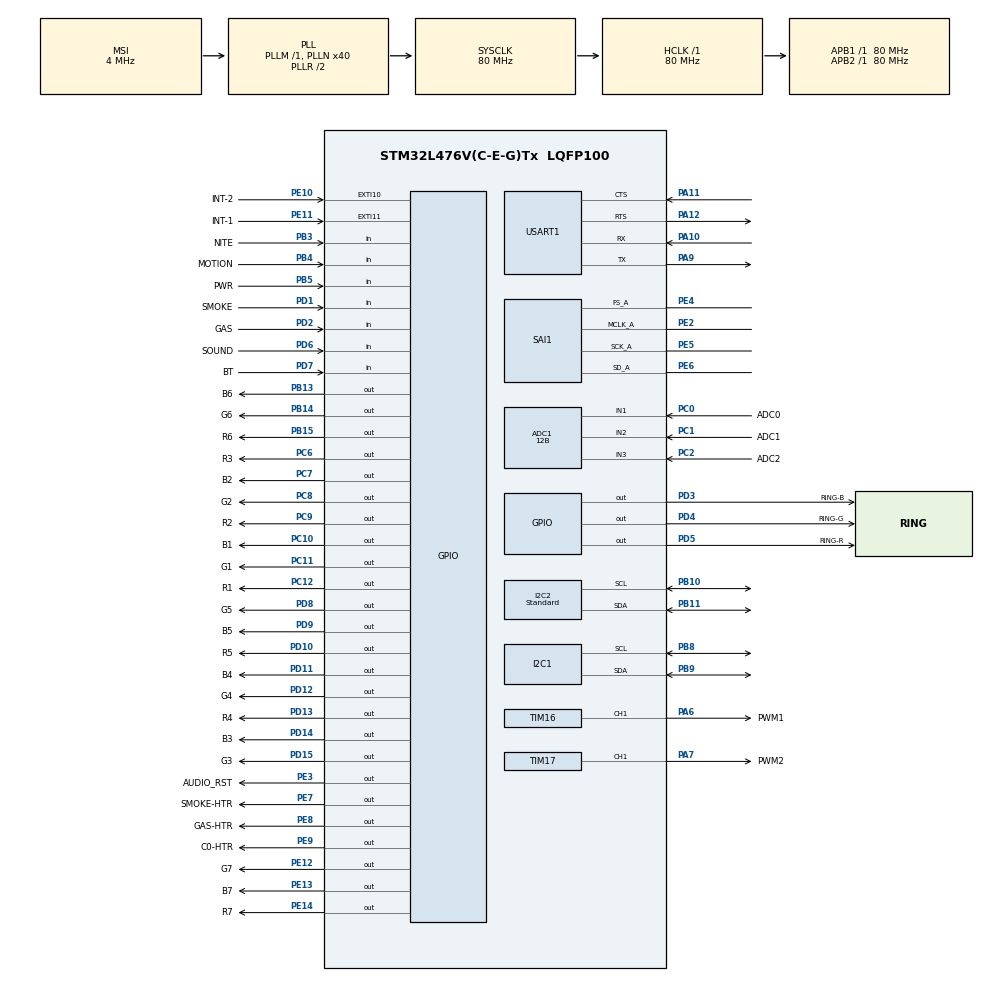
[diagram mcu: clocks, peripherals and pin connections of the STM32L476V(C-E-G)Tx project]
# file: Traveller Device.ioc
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ADC1.Channel-0\#ChannelRegularConversion=ADC_CHANNEL_1
ADC1.Channel-3\#ChannelRegularConversion=ADC_CHANNEL_2
ADC1.Channel-4\#ChannelRegularConversion=ADC_CHANNEL_3
ADC1.ClockPrescaler=ADC_CLOCK_ASYNC_DIV1
ADC1.ContinuousConvMode=ENABLE
ADC1.DMAContinuousRequests=DISABLE
ADC1.DataAlign=ADC_DATAALIGN_RIGHT
ADC1.DiscontinuousConvMode=DISABLE
ADC1.EOCSelection=ADC_EOC_SINGLE_CONV
ADC1.EnableAnalogWatchDog1=false
ADC1.EnableAnalogWatchDog2=false
ADC1.EnableAnalogWatchDog3=false
ADC1.EnableInjectedConversion=DISABLE
ADC1.EnableRegularConversion=ENABLE
ADC1.ExternalTrigConv=ADC_SOFTWARE_START
ADC1.ExternalTrigConvEdge=ADC_EXTERNALTRIGCONVEDGE_NONE
ADC1.LowPowerAutoWait=DISABLE
ADC1.NbrOfConversion=3
ADC1.NbrOfConversionFlag=1
ADC1.OffsetNumber-0\#ChannelRegularConversion=ADC_OFFSET_NONE
ADC1.OffsetNumber-3\#ChannelRegularConversion=ADC_OFFSET_NONE
ADC1.OffsetNumber-4\#ChannelRegularConversion=ADC_OFFSET_NONE
ADC1.Overrun=ADC_OVR_DATA_PRESERVED
ADC1.OversamplingMode=DISABLE
ADC1.Rank-0\#ChannelRegularConversion=1
ADC1.Rank-3\#ChannelRegularConversion=2
ADC1.Rank-4\#ChannelRegularConversion=3
ADC1.Resolution=ADC_RESOLUTION_12B
ADC1.SamplingTime-0\#ChannelRegularConversion=ADC_SAMPLETIME_640CYCLES_5
ADC1.SamplingTime-3\#ChannelRegularConversion=ADC_SAMPLETIME_640CYCLES_5
ADC1.SamplingTime-4\#ChannelRegularConversion=ADC_SAMPLETIME_640CYCLES_5
ADC1.ScanConvMode=ADC_SCAN_ENABLE
ADC1.master=1
Dma.Request0=SAI1_A
Dma.SAI1_A.0.Direction=DMA_MEMORY_TO_PERIPH
Dma.SAI1_A.0.Instance=DMA2_Channel1
Dma.SAI1_A.0.MemDataAlignment=DMA_MDATAALIGN_HALFWORD
Dma.SAI1_A.0.MemInc=DMA_MINC_ENABLE
Dma.SAI1_A.0.Mode=DMA_CIRCULAR
Dma.SAI1_A.0.PeriphDataAlignment=DMA_PDATAALIGN_HALFWORD
Dma.SAI1_A.0.PeriphInc=DMA_PINC_DISABLE
Dma.SAI1_A.0.Priority=DMA_PRIORITY_HIGH
I2C2.Analog_Filter=I2C_ANALOGFILTER_ENABLE
I2C2.I2C_Fall_Time=0
I2C2.I2C_Rise_Time=0
I2C2.I2C_Speed_Mode=I2C_Standard
Mcu.Family=STM32L4
Mcu.Name=STM32L476V(C-E-G)Tx
Mcu.Package=LQFP100
NVIC.DMA2_Channel1_IRQn=true\:0\:0\:false\:false\:true\:false
NVIC.EXTI15_10_IRQn=true\:0\:0\:false\:false\:true\:true
NVIC.I2C1_ER_IRQn=true\:0\:0\:false\:false\:true\:true
NVIC.I2C1_EV_IRQn=true\:0\:0\:false\:false\:true\:true
NVIC.I2C2_ER_IRQn=true\:1\:0\:true\:false\:true\:true
NVIC.I2C2_EV_IRQn=true\:0\:0\:false\:false\:true\:true
NVIC.PriorityGroup=NVIC_PRIORITYGROUP_4
NVIC.SAI1_IRQn=true\:0\:0\:false\:false\:true\:true
PA10.Mode=Asynchronous
PA10.Signal=USART1_RX
PA11.Mode=CTS_RTS
PA11.Signal=USART1_CTS
PA12.Mode=CTS_RTS
PA12.Signal=USART1_RTS
PA6.GPIO_Label=PWM1
PA6.Signal=S_TIM16_CH1
PA7.GPIO_Label=PWM2
PA7.Signal=S_TIM17_CH1
PA9.Mode=Asynchronous
PA9.Signal=USART1_TX
PB10.Mode=I2C
PB10.Signal=I2C2_SCL
PB11.Mode=I2C
PB11.Signal=I2C2_SDA
PB13.GPIO_Label=B6
PB13.Signal=GPIO_Output
PB14.GPIO_Label=G6
PB14.Signal=GPIO_Output
PB15.GPIO_Label=R6
PB15.Signal=GPIO_Output
PB3\ (JTDO-TRACESWO).GPIO_Label=NITE
PB3\ (JTDO-TRACESWO).Signal=GPIO_Input
PB4\ (NJTRST).GPIO_Label=MOTION
PB4\ (NJTRST).Signal=GPIO_Input
PB5.GPIO_Label=PWR
PB5.Signal=GPIO_Input
PB8.Mode=I2C
PB8.Signal=I2C1_SCL
PB9.Mode=I2C
PB9.Signal=I2C1_SDA
PC0.GPIO_Label=ADC0
PC0.Signal=ADCx_IN1
PC1.GPIO_Label=ADC1
PC1.Signal=ADCx_IN2
PC10.GPIO_Label=B1
PC10.Signal=GPIO_Output
PC11.GPIO_Label=G1
PC11.Signal=GPIO_Output
PC12.GPIO_Label=R1
PC12.Signal=GPIO_Output
PC2.GPIO_Label=ADC2
PC2.Signal=ADCx_IN3
PC6.GPIO_Label=R3
PC6.Signal=GPIO_Output
PC7.GPIO_Label=B2
PC7.Signal=GPIO_Output
PC8.GPIO_Label=G2
PC8.Signal=GPIO_Output
PC9.GPIO_Label=R2
PC9.Signal=GPIO_Output
PD1.GPIO_Label=SMOKE
PD1.Signal=GPIO_Input
PD10.GPIO_Label=R5
PD10.Signal=GPIO_Output
PD11.GPIO_Label=B4
PD11.Signal=GPIO_Output
PD12.GPIO_Label=G4
PD12.Signal=GPIO_Output
PD13.GPIO_Label=R4
PD13.Signal=GPIO_Output
PD14.GPIO_Label=B3
PD14.Signal=GPIO_Output
PD15.GPIO_Label=G3
PD15.Signal=GPIO_Output
PD2.GPIO_Label=GAS
PD2.Signal=GPIO_Input
PD3.GPIO_Label=RING-B
PD3.Signal=GPIO_Output
PD4.GPIO_Label=RING-G
PD4.Signal=GPIO_Output
PD5.GPIO_Label=RING-R
PD5.Signal=GPIO_Output
PD6.GPIO_Label=SOUND
PD6.Signal=GPIO_Input
PD7.GPIO_Label=BT
PD7.Signal=GPIO_Input
PD8.GPIO_Label=G5
PD8.Signal=GPIO_Output
PD9.GPIO_Label=B5
PD9.Signal=GPIO_Output
PE10.GPIO_Label=INT-2
PE10.Signal=GPXTI10
PE11.GPIO_Label=INT-1
PE11.Signal=GPXTI11
PE12.GPIO_Label=G7
PE12.Signal=GPIO_Output
PE13.GPIO_Label=B7
PE13.Signal=GPIO_Output
PE14.GPIO_Label=R7
PE14.Signal=GPIO_Output
PE2.Mode=SAI_A_MasterWithClock
PE2.Signal=SAI1_MCLK_A
PE3.GPIO_Label=AUDIO_RST
PE3.Signal=GPIO_Output
PE4.Mode=SAI_A_MasterWithClock
PE4.Signal=SAI1_FS_A
PE5.Mode=SAI_A_MasterWithClock
PE5.Signal=SAI1_SCK_A
PE6.Mode=SAI_A_MasterWithClock
PE6.Signal=SAI1_SD_A
PE7.GPIO_Label=SMOKE-HTR
PE7.Signal=GPIO_Output
PE8.GPIO_Label=GAS-HTR
PE8.Signal=GPIO_Output
PE9.GPIO_Label=C0-HTR
PE9.Signal=GPIO_Output
ProjectManager.HeapSize=0x200
ProjectManager.StackSize=0x400
ProjectManager.TargetToolchain=MDK-ARM V5
RCC.ADCFreq_Value=24000000
RCC.AHBFreq_Value=80000000
RCC.APB1Freq_Value=80000000
RCC.APB1TimFreq_Value=80000000
RCC.APB2Freq_Value=80000000
RCC.APB2TimFreq_Value=80000000
RCC.CortexFreq_Value=80000000
RCC.HCLKFreq_Value=80000000
RCC.HSE_VALUE=8000000
RCC.HSI_VALUE=16000000
RCC.LSE_VALUE=32768
RCC.MSI_VALUE=4000000
RCC.PLLN=40
RCC.PLLSAI1N=48
RCC.PLLSAI1P=RCC_PLLP_DIV17
RCC.PLLSAI1R=RCC_PLLR_DIV8
RCC.SYSCLKFreq_VALUE=80000000
RCC.SYSCLKSource=RCC_SYSCLKSOURCE_PLLCLK
RCC.USBFreq_Value=96000000
RCC.VCOOutputFreq_Value=160000000
SAI1.ActiveFrameLength-SAI_A_MasterWithClock=16
SAI1.AudioFrequency-SAI_A_MasterWithClock=SAI_AUDIO_FREQUENCY_22K
SAI1.DataSize-SAI_A_MasterWithClock=SAI_DATASIZE_16
SAI1.ErrorAudioFreq-SAI_A_MasterWithClock=-88.51 %
SAI1.FIFOThreshold-SAI_A_MasterWithClock=SAI_FIFOTHRESHOLD_1QF
SAI1.FSDefinition-SAI_A_MasterWithClock=SAI_FS_CHANNEL_IDENTIFICATION
SAI1.FSOffset-SAI_A_MasterWithClock=SAI_FS_BEFOREFIRSTBIT
SAI1.FrameLength-SAI_A_MasterWithClock=32
SAI1.Instance-SAI_A_MasterWithClock=SAI$Index_Block_A
SAI1.MClockEnable-SAI_A_MasterWithClock=SAI_MASTERCLOCK_ENABLE
SAI1.OutputDrive-SAI_A_MasterWithClock=SAI_OUTPUTDRIVE_ENABLE
SAI1.RealAudioFreq-SAI_A_MasterWithClock=22.058 KHz
SAI1.SlotActive-SAI_A_MasterWithClock=0x00000003
SAI1.SlotNumber-SAI_A_MasterWithClock=2
SAI1.Synchro-SAI_A_MasterWithClock=SAI_ASYNCHRONOUS
SAI1.VirtualMode-SAI_A_MasterWithClock=VM_MASTER
SAI1.VirtualSlotActive-SAI_A_MasterWithClock=SAI_SLOT_USERSETTING
SAI1.VirtualSlotActive0-SAI_A_MasterWithClock=true
SAI1.VirtualSlotActive1-SAI_A_MasterWithClock=true
SH.ADCx_IN1.0=ADC1_IN1,IN1-Single-Ended
SH.ADCx_IN2.0=ADC1_IN2,IN2-Single-Ended
SH.ADCx_IN3.0=ADC1_IN3,IN3-Single-Ended
SH.S_TIM16_CH1.0=TIM16_CH1,PWM Generation1 CH1
SH.S_TIM17_CH1.0=TIM17_CH1,PWM Generation1 CH1
TIM16.AutoReloadPreload=TIM_AUTORELOAD_PRELOAD_DISABLE
TIM16.Channel=TIM_CHANNEL_1
TIM16.Period=40-1
TIM16.Prescaler=10000-1
TIM16.Pulse=0
TIM17.Channel=TIM_CHANNEL_1
TIM17.Period=40-1
TIM17.Prescaler=10000-1
TIM17.Pulse=9
TIM6.Period=40
TIM6.Prescaler=20000-1
TIM6.TIM_MasterOutputTrigger=TIM_TRGO_UPDATE
USART1.VirtualMode-Asynchronous=VM_ASYNC
VP_TIM16_VS_ClockSourceINT.Mode=Enable_Timer
VP_TIM17_VS_ClockSourceINT.Mode=Enable_Timer
VP_TIM6_VS_ClockSourceINT.Mode=Enable_Timer
VREF+.Mode=InternalMode
VREF+.Signal=VREFBUF_OUT
board=custom

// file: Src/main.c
/**
  ******************************************************************************
  * @file           : main.c
  * @brief          : Main program body
  ******************************************************************************
  ** This notice applies to any and all portions of this file
  * that are not between comment pairs USER CODE BEGIN and
  * USER CODE END. Other portions of this file, whether
  * inserted by the user or by software development tools
  * are owned by their respective copyright owners.
  *
  * COPYRIGHT(c) 2018 STMicroelectronics
  *
  * Redistribution and use in source and binary forms, with or without modification,
  * are permitted provided that the following conditions are met:
  *   1. Redistributions of source code must retain the above copyright notice,
  *      this list of conditions and the following disclaimer.
  *   2. Redistributions in binary form must reproduce the above copyright notice,
  *      this list of conditions and the following disclaimer in the documentation
  *      and/or other materials provided with the distribution.
  *   3. Neither the name of STMicroelectronics nor the names of its contributors
  *      may be used to endorse or promote products derived from this software
  *      without specific prior written permission.
  *
  * THIS SOFTWARE IS PROVIDED BY THE COPYRIGHT HOLDERS AND CONTRIBUTORS "AS IS"
  * AND ANY EXPRESS OR IMPLIED WARRANTIES, INCLUDING, BUT NOT LIMITED TO, THE
  * IMPLIED WARRANTIES OF MERCHANTABILITY AND FITNESS FOR A PARTICULAR PURPOSE ARE
  * DISCLAIMED. IN NO EVENT SHALL THE COPYRIGHT HOLDER OR CONTRIBUTORS BE LIABLE
  * FOR ANY DIRECT, INDIRECT, INCIDENTAL, SPECIAL, EXEMPLARY, OR CONSEQUENTIAL
  * DAMAGES (INCLUDING, BUT NOT LIMITED TO, PROCUREMENT OF SUBSTITUTE GOODS OR
  * SERVICES; LOSS OF USE, DATA, OR PROFITS; OR BUSINESS INTERRUPTION) HOWEVER
  * CAUSED AND ON ANY THEORY OF LIABILITY, WHETHER IN CONTRACT, STRICT LIABILITY,
  * OR TORT (INCLUDING NEGLIGENCE OR OTHERWISE) ARISING IN ANY WAY OUT OF THE USE
  * OF THIS SOFTWARE, EVEN IF ADVISED OF THE POSSIBILITY OF SUCH DAMAGE.
  *
  ******************************************************************************
  */
#include "main.h"
#include "stm32l4xx_hal.h"

/* USER CODE BEGIN Includes */
#define ACC_DEV 0x50
#define LIS3DE_CTRL_REG1             0x20U
#define LIS3DE_CLICK_THS             0x3AU
#define LIS3DE_TIME_LIMIT            0x3BU
#define LIS3DE_CTRL_REG6             0x25U
#define LIS3DE_CLICK_CFG             0x38U
#define AUDIO_FILE_ADDRESS   				0x08098CF0//0x08080000 // 0x08098CF0

// MOTION : 0x08080000 SMOKE : 0x08098CF0 GAS : 0x080B19E0
#define TEMP_ADD (0x40<<1)
__IO int16_t                 UpdatePointer = -1;

#define AUDIO_FILE_SIZE      (100*1024)
#define PLAY_HEADER          	0x2c//0x2C
#define PLAY_BUFF_SIZE       4096
DMA_HandleTypeDef            hSaiDma;

uint16_t                      PlayBuff[PLAY_BUFF_SIZE];
void readSensors();
void trigger();
void temp_hum();
/* USER CODE END Includes */

ADC_HandleTypeDef hadc1;

I2C_HandleTypeDef hi2c1;
I2C_HandleTypeDef hi2c2;

SAI_HandleTypeDef hsai_BlockA1;
DMA_HandleTypeDef hdma_sai1_a;

TIM_HandleTypeDef htim6;
TIM_HandleTypeDef htim16;
TIM_HandleTypeDef htim17;

UART_HandleTypeDef huart1;

/* USER CODE BEGIN PV */
SAI_HandleTypeDef    SaiHandle;
AUDIO_DrvTypeDef            *audio_drv;
#define REFdebounce 50

/* Private variables ---------------------------------------------------------*/
uint32_t flame_a0 = 0x00;
uint32_t CO_a1 = 0x00;
uint32_t smoke_a2 = 0x00;
uint32_t heaterTime = 0x00;
uint32_t offHeaterTime = 0x00;
uint32_t flashredTime = 0x00;
float flameV;
float coV;
float smokeV;
_Bool offCountHeater = 0x00;
_Bool countHeater = 0x00;
_Bool POWERON = 0x00;
_Bool	SMOKEON =	0x00;
_Bool	GASON		=	0x00;
_Bool	MOVEON	=	0x00;
_Bool	SOUNDON	=	0x00;
_Bool NITEON	= 0x00;
_Bool	 SCANROOM = 0x00;
_Bool	BTON		=	0x00;
_Bool POWERON_State = 0x00;
_Bool PWSW = 0x00;
_Bool clear_1 = 1;
_Bool clear_2 = 1;
_Bool clear_3 = 1;
_Bool clear_4 = 1;
_Bool clear_5 = 1;
_Bool clear_6 = 1;
_Bool redCO = 0x00;
_Bool redSmoke = 0x00;
_Bool redFlame = 0x00;
_Bool flashRED = 0x00;
_Bool motionFlag = 0x00;
_Bool firsttimeonly = 0x01;
uint8_t cntboot = 0x00;
uint8_t readAcceloro = 0x00;
uint32_t POWERON_1 = 0;
uint32_t POWERON_0 = 0;
uint32_t sensors 	=	0;
uint32_t sensorsM 	=	0;

uint32_t	SMOKEON_1 =	0x00;
uint32_t	SMOKEON_0 =	0x00;

uint32_t	GASON_1		=	0x00;
uint32_t	GASON_0		=	0x00;

uint32_t	MOVEON_1	=	0x00;
uint32_t	MOVEON_0	=	0x00;

uint32_t	SOUNDON_1	=	0x00;
uint32_t	SOUNDON_0	=	0x00;

uint32_t NITEON_1	= 0x00;
uint32_t NITEON_0	= 0x00;

uint32_t	 SCANROOM_1 = 0x00;
uint32_t	 SCANROOM_0 = 0x00;

uint32_t	BTON_1		=	0x00;
uint32_t	BTON_0		=	0x00;
uint8_t reg1;
uint8_t temph[2] = {0U, 0U};

uint16_t R_HUM = 0x00;
uint16_t R_TEMP = 0x00;

float A_HUM;
float A_TEMP;
/* USER CODE END PV */

void SystemClock_Config(void);
static void MX_GPIO_Init(void);
static void MX_DMA_Init(void);
static void MX_ADC1_Init(void);
static void MX_I2C1_Init(void);
static void MX_I2C2_Init(void);
static void MX_SAI1_Init(void);
static void MX_TIM16_Init(void);
static void MX_TIM17_Init(void);
static void MX_USART1_UART_Init(void);
static void MX_TIM6_Init(void);

void HAL_TIM_MspPostInit(TIM_HandleTypeDef *htim);

/* USER CODE BEGIN PFP */
void heartBeat_loop(uint8_t initial_val, uint8_t end_val, uint8_t n);
void heartBeat_loop2(uint8_t initial_val, uint8_t end_val, uint8_t n);
void test_pwm_blink(void);
void startupF(void);
void shutF(void);
/* Private function prototypes -----------------------------------------------*/

/* USER CODE END PFP */

/* USER CODE BEGIN 0 */
static void Playback_Init(void)
{

	 __HAL_SAI_ENABLE(&hsai_BlockA1);

	if(CS43L22_ID!= cs43l22_drv.ReadID(AUDIO_I2C_ADDRESS))
  {
    Error_Handler();
  }

  audio_drv = &cs43l22_drv;
  audio_drv->Reset(AUDIO_I2C_ADDRESS);
  if(0 != audio_drv->Init(AUDIO_I2C_ADDRESS, OUTPUT_DEVICE_SPEAKER, 100, AUDIO_FREQUENCY_22K))
  {
    Error_Handler();
  }
}
/* USER CODE END 0 */

int main(void)
{

  /* MCU Configuration----------------------------------------------------------*/

  /* Reset of all peripherals, Initializes the Flash interface and the Systick. */
  HAL_Init();

  /* Configure the system clock */
  SystemClock_Config();

  /* USER CODE BEGIN SysInit */
  uint32_t PlaybackPosition   = PLAY_BUFF_SIZE + PLAY_HEADER;
  /* USER CODE END SysInit */

  /* Initialize all configured peripherals */
  MX_GPIO_Init();
  MX_DMA_Init();
  MX_ADC1_Init();
  MX_I2C1_Init();
  MX_I2C2_Init();
  MX_SAI1_Init();
  MX_TIM16_Init();
  MX_TIM17_Init();
  MX_USART1_UART_Init();
  MX_TIM6_Init();
  /* USER CODE BEGIN 2 */
//	HAL_I2C_Master_Transmit(&hi2c1, 0xFF, i2c_Data, 4, 5000);
//	HAL_I2C_Mem_Read(&hi2c1,0x28U, 0x0FU,I2C_MEMADD_SIZE_8BIT, &readAcceloro, 1, 1000);
	HAL_TIM_PWM_Start(&htim16, TIM_CHANNEL_1); //ring light intestiy
	HAL_TIM_PWM_Start(&htim17, TIM_CHANNEL_1);
	//if(*((uint64_t *)AUDIO_FILE_ADDRESS) != 0x017EFE2446464952 ) Error_Handler();
	Playback_Init(); // volume and frequency of audio intitilistation

//	for(int i=0; i < PLAY_BUFF_SIZE; i+=2)
//  {
//    PlayBuff[i]=*((__IO uint16_t *)(AUDIO_FILE_ADDRESS + PLAY_HEADER + i));
//  }
//
//  /* Start the playback */
//  if(0 != audio_drv->Play(AUDIO_I2C_ADDRESS, NULL, 0))
//  {
//    Error_Handler();
//  }
 // if(HAL_OK != HAL_SAI_Transmit_DMA(&hsai_BlockA1, (uint8_t *)PlayBuff, PLAY_BUFF_SIZE)) // should not start here as no audio in the buffer yet
  //{
  //  Error_Handler();
  //}

	countHeater = 0x01;
	//SETTING FOR I2C FOR INTERUPT THE MOTION
	reg1 = 0x77;
	HAL_I2C_Mem_Write(&hi2c1,ACC_DEV, LIS3DE_CTRL_REG1,I2C_MEMADD_SIZE_8BIT, (uint8_t*)&reg1, 1, 1000); // set speed 400khz
	reg1 = 0x69U;//0x12U;
	HAL_Delay(10);
	HAL_I2C_Mem_Write(&hi2c1,ACC_DEV, LIS3DE_CLICK_THS,I2C_MEMADD_SIZE_8BIT, (uint8_t*)&reg1, 1, 1000); //Click threshold set
	reg1 = 0x33U;
	HAL_Delay(10);
	HAL_I2C_Mem_Write(&hi2c1,ACC_DEV, LIS3DE_TIME_LIMIT,I2C_MEMADD_SIZE_8BIT, (uint8_t*)&reg1, 1, 1000);
	HAL_Delay(10);
	reg1 = 0x80U;
	HAL_I2C_Mem_Write(&hi2c1,ACC_DEV, LIS3DE_CTRL_REG6,I2C_MEMADD_SIZE_8BIT, (uint8_t*)&reg1, 1, 1000);
	HAL_Delay(10);
	reg1 = 0x5U;
	HAL_I2C_Mem_Write(&hi2c1,ACC_DEV, LIS3DE_CLICK_CFG,I2C_MEMADD_SIZE_8BIT, (uint8_t*)&reg1, 1, 1000);
	HAL_Delay(10);

	//END OF SETTING FOR I2C FOR INTERUPT THE MOTION

	//START OF READ TEMP
	reg1 = 0xE5; // hold master signal
	HAL_I2C_Mem_Read(&hi2c1, TEMP_ADD, reg1,I2C_MEMADD_SIZE_8BIT, temph, 2, 1000);
	R_HUM = (uint16_t) ((temph[0]<<8) | temph[1]);
	A_HUM = (float)(((125.0 * R_HUM) / 65536.0) - 6.0);
	if(A_HUM < 0)
    A_HUM =  0;
  else if(A_HUM > 100)
    A_HUM = 100;
	reg1 = 0xE0;

	HAL_I2C_Mem_Read(&hi2c1, TEMP_ADD, reg1,I2C_MEMADD_SIZE_8BIT, temph, 2, 1000);
	R_TEMP = (uint16_t) ((temph[0]<<8) | temph[1]);
	A_TEMP = (float)(((175.72 * R_TEMP) / 65536.0) - 46.85);

	//END OF READ TEMP
	motionFlag = 0x0U;
  /* USER CODE END 2 */

  /* Infinite loop */
  /* USER CODE BEGIN WHILE */
  while (1)
  {

		//int position = UpdatePointer;
    //UpdatePointer = -1;
    // Playback when trigger motion
		if(motionFlag & ((sensors >> 7) & 1))
		{
			// copy first part for only one time
			if(firsttimeonly)
		{
			for(int i=0; i < PLAY_BUFF_SIZE; i+=2)
			{
				PlayBuff[i]=*((__IO uint16_t *)(0x08080000 + PLAY_HEADER + i));
			}
				firsttimeonly = 0x00;
				HAL_SAI_Transmit_DMA(&hsai_BlockA1, (uint8_t *)PlayBuff, PLAY_BUFF_SIZE); // try this as each time need to say which chunk of memory buffer to read the data frm
				HAL_SAI_DMAResume(&hsai_BlockA1); // this is because there in trigger() is pause the playback basically means mute the amp z
		}

		int position = UpdatePointer;
    UpdatePointer = -1;

		for(int i = 0; i < PLAY_BUFF_SIZE/2; i++)
    {
      PlayBuff[i+position] = *(uint16_t *)(0x08080000 + PlaybackPosition);
      PlaybackPosition+=2;
    }

		if((PlaybackPosition+PLAY_BUFF_SIZE/2) > AUDIO_FILE_SIZE)
    {
      PlaybackPosition = PLAY_HEADER;
    }

		}

		// smoke code start

				if(redSmoke & ((sensors >> 4) & 1))
		{
			// copy first part for only one time
			if(firsttimeonly)
		{
			for(int i=0; i < PLAY_BUFF_SIZE; i+=2)
			{
				PlayBuff[i]=*((__IO uint16_t *)(0x08098CF0 + PLAY_HEADER + i));
			}
				firsttimeonly = 0x00;
				HAL_SAI_Transmit_DMA(&hsai_BlockA1, (uint8_t *)PlayBuff, PLAY_BUFF_SIZE); // try this as each time need to say which chunk of memory buffer to read the data frm
				HAL_SAI_DMAResume(&hsai_BlockA1); // this is because there in trigger() is pause the playback basically means mute the amp z
		}

		int position = UpdatePointer;
    UpdatePointer = -1;

		for(int i = 0; i < PLAY_BUFF_SIZE/2; i++)
    {
      PlayBuff[i+position] = *(uint16_t *)(0x08098CF0 + PlaybackPosition);
      PlaybackPosition+=2;
    }

		if((PlaybackPosition+PLAY_BUFF_SIZE/2) > AUDIO_FILE_SIZE)
    {
      PlaybackPosition = PLAY_HEADER;
    }

		}
		//smoke code end

		//gas code start
		if(redCO & ((sensors >> 5) & 1))
		{
			// copy first part for only one time
			if(firsttimeonly)
		{
			for(int i=0; i < PLAY_BUFF_SIZE; i+=2)
			{
				PlayBuff[i]=*((__IO uint16_t *)(0x080B19E0 + PLAY_HEADER + i));
			}
				firsttimeonly = 0x00;
				HAL_SAI_Transmit_DMA(&hsai_BlockA1, (uint8_t *)PlayBuff, PLAY_BUFF_SIZE); // try this as each time need to say which chunk of memory buffer to read the data frm
				HAL_SAI_DMAResume(&hsai_BlockA1); // this is because there in trigger() is pause the playback basically means mute the amp z
		}

		int position = UpdatePointer;
    UpdatePointer = -1;

		for(int i = 0; i < PLAY_BUFF_SIZE/2; i++)
    {
      PlayBuff[i+position] = *(uint16_t *)(0x080B19E0 + PlaybackPosition);
      PlaybackPosition+=2;
    }

		if((PlaybackPosition+PLAY_BUFF_SIZE/2) > AUDIO_FILE_SIZE)
    {
      PlaybackPosition = PLAY_HEADER;
    }

		}
		// gas code end

		//while(UpdatePointer==-1){

		//}

    /* Upate the first or the second part of the buffer */
//    for(int i = 0; i < PLAY_BUFF_SIZE/2; i++)
//    {
//      PlayBuff[i+position] = *(uint16_t *)(AUDIO_FILE_ADDRESS + PlaybackPosition);
//      PlaybackPosition+=2;
//    }

//    /* check the end of the file */
//    if((PlaybackPosition+PLAY_BUFF_SIZE/2) > AUDIO_FILE_SIZE)
//    {
//      PlaybackPosition = PLAY_HEADER;
//    }
//
//    if(UpdatePointer != -1)
//    {
//      /* Buffer update time is too long compare to the data transfer time */
//      Error_Handler();
//    }
//
		//Playback_Init();
		if(PWSW) // PWR ON [TurnON001]
		{
			//HAL_GPIO_WritePin(B7_GPIO_Port,B7_Pin,GPIO_PIN_SET);
			//HAL_Delay(500);
			//test_pwm_blink();
			//START
			if(cntboot < 1) //Run this for only first time booting
			{
				HAL_SAI_DMAPause(&hsai_BlockA1);
				HAL_GPIO_WritePin(RING_B_GPIO_Port, RING_B_Pin, GPIO_PIN_SET);
				HAL_GPIO_WritePin(B7_GPIO_Port,B7_Pin,GPIO_PIN_SET);
				cntboot=+1;
				heartBeat_loop2(0,39,1);
				heartBeat_loop(39,9,0);
				heartBeat_loop(9,39,1);
				heartBeat_loop(39,3,0);
				heartBeat_loop(3,39,1);
				heartBeat_loop(39,3,0);
				heartBeat_loop(3,39,1);
				heartBeat_loop(39,3,0);
				heartBeat_loop(3,9,1);
				HAL_SAI_DMAResume(&hsai_BlockA1);
			}

			//Read sensors
			readSensors();
			trigger();
			if((SCANROOM) & (PWSW))
			{
				HAL_SAI_DMAPause(&hsai_BlockA1);
				HAL_GPIO_WritePin(RING_B_GPIO_Port, RING_B_Pin, GPIO_PIN_SET);
				heartBeat_loop2(0,39,1);
				heartBeat_loop(39,9,0);
				heartBeat_loop(9,39,1);
				heartBeat_loop(39,3,0);
				heartBeat_loop(3,39,1);
				heartBeat_loop(39,3,0);
				heartBeat_loop(3,39,1);
				heartBeat_loop(39,3,0);
				heartBeat_loop(3,9,1);
				SCANROOM = 0;
				HAL_SAI_DMAResume(&hsai_BlockA1);
			}

			if((sensors >> 4) & 1)
			{
				if(redSmoke)
				{
				HAL_GPIO_WritePin(B1_GPIO_Port, B1_Pin, GPIO_PIN_RESET);
				HAL_GPIO_WritePin(R1_GPIO_Port, R1_Pin, GPIO_PIN_SET);
				}
				else
				{
				HAL_GPIO_WritePin(R1_GPIO_Port, R1_Pin, GPIO_PIN_RESET);
				HAL_GPIO_WritePin(B1_GPIO_Port, B1_Pin, GPIO_PIN_SET);
				}
			}
			else
			{
				HAL_GPIO_WritePin(B1_GPIO_Port, B1_Pin, GPIO_PIN_RESET);
				HAL_GPIO_WritePin(R1_GPIO_Port, R1_Pin, GPIO_PIN_RESET);
			}

			if((sensors >> 5) & 1)
			{
				if(redCO)
				{
					HAL_GPIO_WritePin(B2_GPIO_Port, B2_Pin, GPIO_PIN_RESET);
					HAL_GPIO_WritePin(R2_GPIO_Port, R2_Pin, GPIO_PIN_SET);
				}
				else
				{
				HAL_GPIO_WritePin(B2_GPIO_Port, B2_Pin, GPIO_PIN_SET);
				HAL_GPIO_WritePin(R2_GPIO_Port, R2_Pin, GPIO_PIN_RESET);
				}
			}
			else
			{
				HAL_GPIO_WritePin(B2_GPIO_Port, B2_Pin, GPIO_PIN_RESET);
				HAL_GPIO_WritePin(R2_GPIO_Port, R2_Pin, GPIO_PIN_RESET);
			}
			if((sensors >> 6) & 1)
			{
				HAL_GPIO_WritePin(B5_GPIO_Port, B5_Pin, GPIO_PIN_SET);

			}
			else
			{
				HAL_GPIO_WritePin(B5_GPIO_Port, B5_Pin, GPIO_PIN_RESET);
			}

			if((sensors >> 7) & 1) // MOTION LIGHT
			{
				if(motionFlag)
				{
					HAL_GPIO_WritePin(B6_GPIO_Port, B6_Pin, GPIO_PIN_RESET);
					HAL_GPIO_WritePin(R6_GPIO_Port, R6_Pin, GPIO_PIN_SET);
				}
				else
				{
				HAL_GPIO_WritePin(B6_GPIO_Port, B6_Pin, GPIO_PIN_SET);
				HAL_GPIO_WritePin(R6_GPIO_Port, R6_Pin, GPIO_PIN_RESET);
				}
				//HAL_GPIO_WritePin(B6_GPIO_Port, B6_Pin, GPIO_PIN_SET);
			}
			else
			{
				HAL_GPIO_WritePin(B6_GPIO_Port, B6_Pin, GPIO_PIN_RESET);
				HAL_GPIO_WritePin(R6_GPIO_Port, R6_Pin, GPIO_PIN_RESET);
			}

			if((sensors >> 8) & 1)
			{
				HAL_GPIO_WritePin(B3_GPIO_Port, B3_Pin, GPIO_PIN_SET);
			}
			else
			{
				HAL_GPIO_WritePin(B3_GPIO_Port, B3_Pin, GPIO_PIN_RESET);
			}

			if((sensors >> 9) & 1)
			{
				HAL_GPIO_WritePin(B4_GPIO_Port, B4_Pin, GPIO_PIN_SET);
			}
			else
			{
				HAL_GPIO_WritePin(B4_GPIO_Port, B4_Pin, GPIO_PIN_RESET);
			}

		}
		else //PWR OFF  [TurnOFF001]
		{
			if(cntboot>=1) // run this if the turn on routine have run before.
				{
					//Off light S
					heartBeat_loop2(9,3,0);
					heartBeat_loop(3,39,1);
					heartBeat_loop(39,3,0);
					heartBeat_loop(3,39,1);
					heartBeat_loop(39,3,0);
					heartBeat_loop(3,39,1);
					heartBeat_loop(39,9,0);
					heartBeat_loop(9,39,1);
					heartBeat_loop(39,1,0);
				}

			HAL_GPIO_WritePin(RING_B_GPIO_Port, RING_B_Pin, GPIO_PIN_RESET);
			HAL_GPIO_WritePin(B7_GPIO_Port,B7_Pin,GPIO_PIN_RESET);

			cntboot=0;
		}

  /* USER CODE END WHILE */

  }

}

void SystemClock_Config(void)
{

  RCC_OscInitTypeDef RCC_OscInitStruct;
  RCC_ClkInitTypeDef RCC_ClkInitStruct;
  RCC_PeriphCLKInitTypeDef PeriphClkInit;

    /**Initializes the CPU, AHB and APB busses clocks
    */
  RCC_OscInitStruct.OscillatorType = RCC_OSCILLATORTYPE_MSI;
  RCC_OscInitStruct.MSIState = RCC_MSI_ON;
  RCC_OscInitStruct.MSICalibrationValue = 0;
  RCC_OscInitStruct.MSIClockRange = RCC_MSIRANGE_6;
  RCC_OscInitStruct.PLL.PLLState = RCC_PLL_ON;
  RCC_OscInitStruct.PLL.PLLSource = RCC_PLLSOURCE_MSI;
  RCC_OscInitStruct.PLL.PLLM = 1;
  RCC_OscInitStruct.PLL.PLLN = 40;
  RCC_OscInitStruct.PLL.PLLP = RCC_PLLP_DIV7;
  RCC_OscInitStruct.PLL.PLLQ = RCC_PLLQ_DIV2;
  RCC_OscInitStruct.PLL.PLLR = RCC_PLLR_DIV2;
  if (HAL_RCC_OscConfig(&RCC_OscInitStruct) != HAL_OK)
  {
    _Error_Handler(__FILE__, __LINE__);
  }

    /**Initializes the CPU, AHB and APB busses clocks
    */
  RCC_ClkInitStruct.ClockType = RCC_CLOCKTYPE_HCLK|RCC_CLOCKTYPE_SYSCLK
                              |RCC_CLOCKTYPE_PCLK1|RCC_CLOCKTYPE_PCLK2;
  RCC_ClkInitStruct.SYSCLKSource = RCC_SYSCLKSOURCE_PLLCLK;
  RCC_ClkInitStruct.AHBCLKDivider = RCC_SYSCLK_DIV1;
  RCC_ClkInitStruct.APB1CLKDivider = RCC_HCLK_DIV1;
  RCC_ClkInitStruct.APB2CLKDivider = RCC_HCLK_DIV1;

  if (HAL_RCC_ClockConfig(&RCC_ClkInitStruct, FLASH_LATENCY_4) != HAL_OK)
  {
    _Error_Handler(__FILE__, __LINE__);
  }

  PeriphClkInit.PeriphClockSelection = RCC_PERIPHCLK_USART1|RCC_PERIPHCLK_SAI1
                              |RCC_PERIPHCLK_I2C1|RCC_PERIPHCLK_I2C2
                              |RCC_PERIPHCLK_ADC;
  PeriphClkInit.Usart1ClockSelection = RCC_USART1CLKSOURCE_PCLK2;
  PeriphClkInit.I2c1ClockSelection = RCC_I2C1CLKSOURCE_PCLK1;
  PeriphClkInit.I2c2ClockSelection = RCC_I2C2CLKSOURCE_PCLK1;
  PeriphClkInit.Sai1ClockSelection = RCC_SAI1CLKSOURCE_PLLSAI1;
  PeriphClkInit.AdcClockSelection = RCC_ADCCLKSOURCE_PLLSAI1;
  PeriphClkInit.PLLSAI1.PLLSAI1Source = RCC_PLLSOURCE_MSI;
  PeriphClkInit.PLLSAI1.PLLSAI1M = 1;
  PeriphClkInit.PLLSAI1.PLLSAI1N = 48;
  PeriphClkInit.PLLSAI1.PLLSAI1P = RCC_PLLP_DIV17;
  PeriphClkInit.PLLSAI1.PLLSAI1Q = RCC_PLLQ_DIV2;
  PeriphClkInit.PLLSAI1.PLLSAI1R = RCC_PLLR_DIV8;
  PeriphClkInit.PLLSAI1.PLLSAI1ClockOut = RCC_PLLSAI1_SAI1CLK|RCC_PLLSAI1_ADC1CLK;
  if (HAL_RCCEx_PeriphCLKConfig(&PeriphClkInit) != HAL_OK)
  {
    _Error_Handler(__FILE__, __LINE__);
  }

    /**Configure the main internal regulator output voltage
    */
  if (HAL_PWREx_ControlVoltageScaling(PWR_REGULATOR_VOLTAGE_SCALE1) != HAL_OK)
  {
    _Error_Handler(__FILE__, __LINE__);
  }

    /**Configure the Systick interrupt time
    */
  HAL_SYSTICK_Config(HAL_RCC_GetHCLKFreq()/1000);

    /**Configure the Systick
    */
  HAL_SYSTICK_CLKSourceConfig(SYSTICK_CLKSOURCE_HCLK);

  /* SysTick_IRQn interrupt configuration */
  HAL_NVIC_SetPriority(SysTick_IRQn, 0, 0);
}

/* ADC1 init function */
static void MX_ADC1_Init(void)
{

  ADC_MultiModeTypeDef multimode;
  ADC_ChannelConfTypeDef sConfig;

    /**Common config
    */
  hadc1.Instance = ADC1;
  hadc1.Init.ClockPrescaler = ADC_CLOCK_ASYNC_DIV1;
  hadc1.Init.Resolution = ADC_RESOLUTION_12B;
  hadc1.Init.DataAlign = ADC_DATAALIGN_RIGHT;
  hadc1.Init.ScanConvMode = ADC_SCAN_ENABLE;
  hadc1.Init.EOCSelection = ADC_EOC_SINGLE_CONV;
  hadc1.Init.LowPowerAutoWait = DISABLE;
  hadc1.Init.ContinuousConvMode = ENABLE;
  hadc1.Init.NbrOfConversion = 3;
  hadc1.Init.DiscontinuousConvMode = DISABLE;
  hadc1.Init.NbrOfDiscConversion = 1;
  hadc1.Init.ExternalTrigConv = ADC_SOFTWARE_START;
  hadc1.Init.ExternalTrigConvEdge = ADC_EXTERNALTRIGCONVEDGE_NONE;
  hadc1.Init.DMAContinuousRequests = DISABLE;
  hadc1.Init.Overrun = ADC_OVR_DATA_PRESERVED;
  hadc1.Init.OversamplingMode = DISABLE;
  if (HAL_ADC_Init(&hadc1) != HAL_OK)
  {
    _Error_Handler(__FILE__, __LINE__);
  }

    /**Configure the ADC multi-mode
    */
  multimode.Mode = ADC_MODE_INDEPENDENT;
  if (HAL_ADCEx_MultiModeConfigChannel(&hadc1, &multimode) != HAL_OK)
  {
    _Error_Handler(__FILE__, __LINE__);
  }

    /**Configure Regular Channel
    */
  sConfig.Channel = ADC_CHANNEL_1;
  sConfig.Rank = ADC_REGULAR_RANK_1;
  sConfig.SamplingTime = ADC_SAMPLETIME_640CYCLES_5;
  sConfig.SingleDiff = ADC_SINGLE_ENDED;
  sConfig.OffsetNumber = ADC_OFFSET_NONE;
  sConfig.Offset = 0;
  if (HAL_ADC_ConfigChannel(&hadc1, &sConfig) != HAL_OK)
  {
    _Error_Handler(__FILE__, __LINE__);
  }

    /**Configure Regular Channel
    */
  sConfig.Channel = ADC_CHANNEL_2;
  sConfig.Rank = ADC_REGULAR_RANK_2;
  if (HAL_ADC_ConfigChannel(&hadc1, &sConfig) != HAL_OK)
  {
    _Error_Handler(__FILE__, __LINE__);
  }

    /**Configure Regular Channel
    */
  sConfig.Channel = ADC_CHANNEL_3;
  sConfig.Rank = ADC_REGULAR_RANK_3;
  if (HAL_ADC_ConfigChannel(&hadc1, &sConfig) != HAL_OK)
  {
    _Error_Handler(__FILE__, __LINE__);
  }

}

/* I2C1 init function */
static void MX_I2C1_Init(void)
{

  hi2c1.Instance = I2C1;
  hi2c1.Init.Timing = 0x10909CEC;
  hi2c1.Init.OwnAddress1 = 0;
  hi2c1.Init.AddressingMode = I2C_ADDRESSINGMODE_7BIT;
  hi2c1.Init.DualAddressMode = I2C_DUALADDRESS_DISABLE;
  hi2c1.Init.OwnAddress2 = 0;
  hi2c1.Init.OwnAddress2Masks = I2C_OA2_NOMASK;
  hi2c1.Init.GeneralCallMode = I2C_GENERALCALL_DISABLE;
  hi2c1.Init.NoStretchMode = I2C_NOSTRETCH_DISABLE;
  if (HAL_I2C_Init(&hi2c1) != HAL_OK)
  {
    _Error_Handler(__FILE__, __LINE__);
  }

    /**Configure Analogue filter
    */
  if (HAL_I2CEx_ConfigAnalogFilter(&hi2c1, I2C_ANALOGFILTER_ENABLE) != HAL_OK)
  {
    _Error_Handler(__FILE__, __LINE__);
  }

    /**Configure Digital filter
    */
  if (HAL_I2CEx_ConfigDigitalFilter(&hi2c1, 0) != HAL_OK)
  {
    _Error_Handler(__FILE__, __LINE__);
  }

}

/* I2C2 init function */
static void MX_I2C2_Init(void)
{

  hi2c2.Instance = I2C2;
  hi2c2.Init.Timing = 0x10909CEC;
  hi2c2.Init.OwnAddress1 = 0;
  hi2c2.Init.AddressingMode = I2C_ADDRESSINGMODE_7BIT;
  hi2c2.Init.DualAddressMode = I2C_DUALADDRESS_DISABLE;
  hi2c2.Init.OwnAddress2 = 0;
  hi2c2.Init.OwnAddress2Masks = I2C_OA2_NOMASK;
  hi2c2.Init.GeneralCallMode = I2C_GENERALCALL_DISABLE;
  hi2c2.Init.NoStretchMode = I2C_NOSTRETCH_DISABLE;
  if (HAL_I2C_Init(&hi2c2) != HAL_OK)
  {
    _Error_Handler(__FILE__, __LINE__);
  }

    /**Configure Analogue filter
    */
  if (HAL_I2CEx_ConfigAnalogFilter(&hi2c2, I2C_ANALOGFILTER_ENABLE) != HAL_OK)
  {
    _Error_Handler(__FILE__, __LINE__);
  }

    /**Configure Digital filter
    */
  if (HAL_I2CEx_ConfigDigitalFilter(&hi2c2, 0) != HAL_OK)
  {
    _Error_Handler(__FILE__, __LINE__);
  }

}

/* SAI1 init function */
static void MX_SAI1_Init(void)
{

  hsai_BlockA1.Instance = SAI1_Block_A;
  hsai_BlockA1.Init.Protocol = SAI_FREE_PROTOCOL;
  hsai_BlockA1.Init.AudioMode = SAI_MODEMASTER_TX;
  hsai_BlockA1.Init.DataSize = SAI_DATASIZE_16;
  hsai_BlockA1.Init.FirstBit = SAI_FIRSTBIT_MSB;
  hsai_BlockA1.Init.ClockStrobing = SAI_CLOCKSTROBING_FALLINGEDGE;
  hsai_BlockA1.Init.Synchro = SAI_ASYNCHRONOUS;
  hsai_BlockA1.Init.OutputDrive = SAI_OUTPUTDRIVE_ENABLE;
  hsai_BlockA1.Init.NoDivider = SAI_MASTERDIVIDER_ENABLE;
  hsai_BlockA1.Init.FIFOThreshold = SAI_FIFOTHRESHOLD_1QF;
  hsai_BlockA1.Init.AudioFrequency = SAI_AUDIO_FREQUENCY_22K;
  hsai_BlockA1.Init.SynchroExt = SAI_SYNCEXT_DISABLE;
  hsai_BlockA1.Init.MonoStereoMode = SAI_MONOMODE;//SAI_STEREOMODE;
  hsai_BlockA1.Init.CompandingMode = SAI_NOCOMPANDING;
  hsai_BlockA1.Init.TriState = SAI_OUTPUT_NOTRELEASED;
  hsai_BlockA1.FrameInit.FrameLength = 32;
  hsai_BlockA1.FrameInit.ActiveFrameLength = 16;
  hsai_BlockA1.FrameInit.FSDefinition = SAI_FS_CHANNEL_IDENTIFICATION;
  hsai_BlockA1.FrameInit.FSPolarity = SAI_FS_ACTIVE_LOW;
  hsai_BlockA1.FrameInit.FSOffset = SAI_FS_BEFOREFIRSTBIT;
  hsai_BlockA1.SlotInit.FirstBitOffset = 0;
  hsai_BlockA1.SlotInit.SlotSize = SAI_SLOTSIZE_DATASIZE;
  hsai_BlockA1.SlotInit.SlotNumber = 2;
  hsai_BlockA1.SlotInit.SlotActive = 0x00000003;
  if (HAL_SAI_Init(&hsai_BlockA1) != HAL_OK)
  {
    _Error_Handler(__FILE__, __LINE__);
  }

}

/* TIM6 init function */
static void MX_TIM6_Init(void)
{

  TIM_MasterConfigTypeDef sMasterConfig;

  htim6.Instance = TIM6;
  htim6.Init.Prescaler = 20000-1;
  htim6.Init.CounterMode = TIM_COUNTERMODE_UP;
  htim6.Init.Period = 40;
  htim6.Init.AutoReloadPreload = TIM_AUTORELOAD_PRELOAD_DISABLE;
  if (HAL_TIM_Base_Init(&htim6) != HAL_OK)
  {
    _Error_Handler(__FILE__, __LINE__);
  }

  sMasterConfig.MasterOutputTrigger = TIM_TRGO_UPDATE;
  sMasterConfig.MasterSlaveMode = TIM_MASTERSLAVEMODE_DISABLE;
  if (HAL_TIMEx_MasterConfigSynchronization(&htim6, &sMasterConfig) != HAL_OK)
  {
    _Error_Handler(__FILE__, __LINE__);
  }

}

/* TIM16 init function */
static void MX_TIM16_Init(void)
{

  TIM_OC_InitTypeDef sConfigOC;
  TIM_BreakDeadTimeConfigTypeDef sBreakDeadTimeConfig;

  htim16.Instance = TIM16;
  htim16.Init.Prescaler = 10000-1;
  htim16.Init.CounterMode = TIM_COUNTERMODE_UP;
  htim16.Init.Period = 40-1;
  htim16.Init.ClockDivision = TIM_CLOCKDIVISION_DIV1;
  htim16.Init.RepetitionCounter = 0;
  htim16.Init.AutoReloadPreload = TIM_AUTORELOAD_PRELOAD_DISABLE;
  if (HAL_TIM_Base_Init(&htim16) != HAL_OK)
  {
    _Error_Handler(__FILE__, __LINE__);
  }

  if (HAL_TIM_PWM_Init(&htim16) != HAL_OK)
  {
    _Error_Handler(__FILE__, __LINE__);
  }

  sConfigOC.OCMode = TIM_OCMODE_PWM1;
  sConfigOC.Pulse = 0;
  sConfigOC.OCPolarity = TIM_OCPOLARITY_HIGH;
  sConfigOC.OCNPolarity = TIM_OCNPOLARITY_HIGH;
  sConfigOC.OCFastMode = TIM_OCFAST_DISABLE;
  sConfigOC.OCIdleState = TIM_OCIDLESTATE_RESET;
  sConfigOC.OCNIdleState = TIM_OCNIDLESTATE_RESET;
  if (HAL_TIM_PWM_ConfigChannel(&htim16, &sConfigOC, TIM_CHANNEL_1) != HAL_OK)
  {
    _Error_Handler(__FILE__, __LINE__);
  }

  sBreakDeadTimeConfig.OffStateRunMode = TIM_OSSR_DISABLE;
  sBreakDeadTimeConfig.OffStateIDLEMode = TIM_OSSI_DISABLE;
  sBreakDeadTimeConfig.LockLevel = TIM_LOCKLEVEL_OFF;
  sBreakDeadTimeConfig.DeadTime = 0;
  sBreakDeadTimeConfig.BreakState = TIM_BREAK_DISABLE;
  sBreakDeadTimeConfig.BreakPolarity = TIM_BREAKPOLARITY_HIGH;
  sBreakDeadTimeConfig.BreakFilter = 0;
  sBreakDeadTimeConfig.AutomaticOutput = TIM_AUTOMATICOUTPUT_DISABLE;
  if (HAL_TIMEx_ConfigBreakDeadTime(&htim16, &sBreakDeadTimeConfig) != HAL_OK)
  {
    _Error_Handler(__FILE__, __LINE__);
  }

  HAL_TIM_MspPostInit(&htim16);

}

/* TIM17 init function */
static void MX_TIM17_Init(void)
{

  TIM_OC_InitTypeDef sConfigOC;
  TIM_BreakDeadTimeConfigTypeDef sBreakDeadTimeConfig;

  htim17.Instance = TIM17;
  htim17.Init.Prescaler = 10000-1;
  htim17.Init.CounterMode = TIM_COUNTERMODE_UP;
  htim17.Init.Period = 40-1;
  htim17.Init.ClockDivision = TIM_CLOCKDIVISION_DIV1;
  htim17.Init.RepetitionCounter = 0;
  htim17.Init.AutoReloadPreload = TIM_AUTORELOAD_PRELOAD_DISABLE;
  if (HAL_TIM_Base_Init(&htim17) != HAL_OK)
  {
    _Error_Handler(__FILE__, __LINE__);
  }

  if (HAL_TIM_PWM_Init(&htim17) != HAL_OK)
  {
    _Error_Handler(__FILE__, __LINE__);
  }

  sConfigOC.OCMode = TIM_OCMODE_PWM1;
  sConfigOC.Pulse = 9;
  sConfigOC.OCPolarity = TIM_OCPOLARITY_HIGH;
  sConfigOC.OCNPolarity = TIM_OCNPOLARITY_HIGH;
  sConfigOC.OCFastMode = TIM_OCFAST_DISABLE;
  sConfigOC.OCIdleState = TIM_OCIDLESTATE_RESET;
  sConfigOC.OCNIdleState = TIM_OCNIDLESTATE_RESET;
  if (HAL_TIM_PWM_ConfigChannel(&htim17, &sConfigOC, TIM_CHANNEL_1) != HAL_OK)
  {
    _Error_Handler(__FILE__, __LINE__);
  }

  sBreakDeadTimeConfig.OffStateRunMode = TIM_OSSR_DISABLE;
  sBreakDeadTimeConfig.OffStateIDLEMode = TIM_OSSI_DISABLE;
  sBreakDeadTimeConfig.LockLevel = TIM_LOCKLEVEL_OFF;
  sBreakDeadTimeConfig.DeadTime = 0;
  sBreakDeadTimeConfig.BreakState = TIM_BREAK_DISABLE;
  sBreakDeadTimeConfig.BreakPolarity = TIM_BREAKPOLARITY_HIGH;
  sBreakDeadTimeConfig.BreakFilter = 0;
  sBreakDeadTimeConfig.AutomaticOutput = TIM_AUTOMATICOUTPUT_DISABLE;
  if (HAL_TIMEx_ConfigBreakDeadTime(&htim17, &sBreakDeadTimeConfig) != HAL_OK)
  {
    _Error_Handler(__FILE__, __LINE__);
  }

  HAL_TIM_MspPostInit(&htim17);

}

/* USART1 init function */
static void MX_USART1_UART_Init(void)
{

  huart1.Instance = USART1;
  huart1.Init.BaudRate = 115200;
  huart1.Init.WordLength = UART_WORDLENGTH_8B;
  huart1.Init.StopBits = UART_STOPBITS_1;
  huart1.Init.Parity = UART_PARITY_NONE;
  huart1.Init.Mode = UART_MODE_TX_RX;
  huart1.Init.HwFlowCtl = UART_HWCONTROL_RTS_CTS;
  huart1.Init.OverSampling = UART_OVERSAMPLING_16;
  huart1.Init.OneBitSampling = UART_ONE_BIT_SAMPLE_DISABLE;
  huart1.AdvancedInit.AdvFeatureInit = UART_ADVFEATURE_NO_INIT;
  if (HAL_UART_Init(&huart1) != HAL_OK)
  {
    _Error_Handler(__FILE__, __LINE__);
  }

}

static void MX_DMA_Init(void)
{
  /* DMA controller clock enable */
  __HAL_RCC_DMA2_CLK_ENABLE();

  /* DMA interrupt init */
  /* DMA2_Channel1_IRQn interrupt configuration */
  HAL_NVIC_SetPriority(DMA2_Channel1_IRQn, 0, 0);
  HAL_NVIC_EnableIRQ(DMA2_Channel1_IRQn);

}

/** Configure pins as
        * Analog
        * Input
        * Output
        * EVENT_OUT
        * EXTI
*/
static void MX_GPIO_Init(void)
{

  GPIO_InitTypeDef GPIO_InitStruct;

  /* GPIO Ports Clock Enable */
  __HAL_RCC_GPIOE_CLK_ENABLE();
  __HAL_RCC_GPIOC_CLK_ENABLE();
  __HAL_RCC_GPIOA_CLK_ENABLE();
  __HAL_RCC_GPIOB_CLK_ENABLE();
  __HAL_RCC_GPIOD_CLK_ENABLE();

  /*Configure GPIO pin Output Level */
  HAL_GPIO_WritePin(GPIOE, AUDIO_RST_Pin|SMOKE_HTR_Pin|GAS_HTR_Pin|C0_HTR_Pin
                          |G7_Pin|B7_Pin|R7_Pin, GPIO_PIN_RESET);

  /*Configure GPIO pin Output Level */
  HAL_GPIO_WritePin(GPIOB, B6_Pin|G6_Pin|R6_Pin, GPIO_PIN_RESET);

  /*Configure GPIO pin Output Level */
  HAL_GPIO_WritePin(GPIOD, G5_Pin|B5_Pin|R5_Pin|B4_Pin
                          |G4_Pin|R4_Pin|B3_Pin|G3_Pin
                          |RING_B_Pin|RING_G_Pin|RING_R_Pin, GPIO_PIN_RESET);

  /*Configure GPIO pin Output Level */
  HAL_GPIO_WritePin(GPIOC, R3_Pin|B2_Pin|G2_Pin|R2_Pin
                          |B1_Pin|G1_Pin|R1_Pin, GPIO_PIN_RESET);

  /*Configure GPIO pins : AUDIO_RST_Pin SMOKE_HTR_Pin GAS_HTR_Pin C0_HTR_Pin
                           G7_Pin B7_Pin R7_Pin */
  GPIO_InitStruct.Pin = AUDIO_RST_Pin|SMOKE_HTR_Pin|GAS_HTR_Pin|C0_HTR_Pin
                          |G7_Pin|B7_Pin|R7_Pin;
  GPIO_InitStruct.Mode = GPIO_MODE_OUTPUT_PP;
  GPIO_InitStruct.Pull = GPIO_NOPULL;
  GPIO_InitStruct.Speed = GPIO_SPEED_FREQ_LOW;
  HAL_GPIO_Init(GPIOE, &GPIO_InitStruct);

  /*Configure GPIO pins : INT_2_Pin INT_1_Pin */
  GPIO_InitStruct.Pin = INT_2_Pin|INT_1_Pin;
  GPIO_InitStruct.Mode = GPIO_MODE_IT_RISING;
  GPIO_InitStruct.Pull = GPIO_NOPULL;
  HAL_GPIO_Init(GPIOE, &GPIO_InitStruct);

  /*Configure GPIO pins : B6_Pin G6_Pin R6_Pin */
  GPIO_InitStruct.Pin = B6_Pin|G6_Pin|R6_Pin;
  GPIO_InitStruct.Mode = GPIO_MODE_OUTPUT_PP;
  GPIO_InitStruct.Pull = GPIO_NOPULL;
  GPIO_InitStruct.Speed = GPIO_SPEED_FREQ_LOW;
  HAL_GPIO_Init(GPIOB, &GPIO_InitStruct);

  /*Configure GPIO pins : G5_Pin B5_Pin R5_Pin B4_Pin
                           G4_Pin R4_Pin B3_Pin G3_Pin
                           RING_B_Pin RING_G_Pin RING_R_Pin */
  GPIO_InitStruct.Pin = G5_Pin|B5_Pin|R5_Pin|B4_Pin
                          |G4_Pin|R4_Pin|B3_Pin|G3_Pin
                          |RING_B_Pin|RING_G_Pin|RING_R_Pin;
  GPIO_InitStruct.Mode = GPIO_MODE_OUTPUT_PP;
  GPIO_InitStruct.Pull = GPIO_NOPULL;
  GPIO_InitStruct.Speed = GPIO_SPEED_FREQ_LOW;
  HAL_GPIO_Init(GPIOD, &GPIO_InitStruct);

  /*Configure GPIO pins : R3_Pin B2_Pin G2_Pin R2_Pin
                           B1_Pin G1_Pin R1_Pin */
  GPIO_InitStruct.Pin = R3_Pin|B2_Pin|G2_Pin|R2_Pin
                          |B1_Pin|G1_Pin|R1_Pin;
  GPIO_InitStruct.Mode = GPIO_MODE_OUTPUT_PP;
  GPIO_InitStruct.Pull = GPIO_NOPULL;
  GPIO_InitStruct.Speed = GPIO_SPEED_FREQ_LOW;
  HAL_GPIO_Init(GPIOC, &GPIO_InitStruct);

  /*Configure GPIO pins : SMOKE_Pin GAS_Pin SOUND_Pin BT_Pin */
  GPIO_InitStruct.Pin = SMOKE_Pin|GAS_Pin|SOUND_Pin|BT_Pin;
  GPIO_InitStruct.Mode = GPIO_MODE_INPUT;
  GPIO_InitStruct.Pull = GPIO_NOPULL;
  HAL_GPIO_Init(GPIOD, &GPIO_InitStruct);

  /*Configure GPIO pins : NITE_Pin MOTION_Pin PWR_Pin */
  GPIO_InitStruct.Pin = NITE_Pin|MOTION_Pin|PWR_Pin;
  GPIO_InitStruct.Mode = GPIO_MODE_INPUT;
  GPIO_InitStruct.Pull = GPIO_NOPULL;
  HAL_GPIO_Init(GPIOB, &GPIO_InitStruct);

  /* EXTI interrupt init*/
  HAL_NVIC_SetPriority(EXTI15_10_IRQn, 0, 0);
  HAL_NVIC_EnableIRQ(EXTI15_10_IRQn);

}

/* USER CODE BEGIN 4 */

void test_pwm_blink(void)
{
		for(int x = 0; x<40; )
  {

		HAL_GPIO_WritePin(RING_R_GPIO_Port, RING_R_Pin, GPIO_PIN_SET);
		HAL_GPIO_WritePin(RING_G_GPIO_Port, RING_G_Pin, GPIO_PIN_SET);
		HAL_GPIO_WritePin(RING_B_GPIO_Port, RING_B_Pin, GPIO_PIN_SET);
		TIM16->CCR1= x;
		x=x+5;
		HAL_Delay(50);
  }

		HAL_GPIO_TogglePin(RING_R_GPIO_Port, RING_R_Pin);
		HAL_GPIO_TogglePin(RING_G_GPIO_Port, RING_G_Pin);
		HAL_GPIO_TogglePin(RING_B_GPIO_Port, RING_B_Pin);
		HAL_Delay(50);
}
void HAL_SYSTICK_Callback(void)
{
	POWERON = HAL_GPIO_ReadPin(PWR_GPIO_Port, PWR_Pin);
	SMOKEON =	HAL_GPIO_ReadPin(SMOKE_GPIO_Port,SMOKE_Pin);
	GASON		= HAL_GPIO_ReadPin(GAS_GPIO_Port,GAS_Pin);
	MOVEON	=	HAL_GPIO_ReadPin(MOTION_GPIO_Port,MOTION_Pin);
	SOUNDON	= HAL_GPIO_ReadPin(SOUND_GPIO_Port,SOUND_Pin);
	BTON		= HAL_GPIO_ReadPin(BT_GPIO_Port,BT_Pin);
	NITEON	= HAL_GPIO_ReadPin(NITE_GPIO_Port,NITE_Pin);

	if(POWERON != 1)  //Pressed
	{
		//PWSW = 0;
		POWERON_1 ++; // Is a count var of button preess increment 1 by 1ms
		POWERON_0 = 0; // debounce the zero value
		if(POWERON_1 >= REFdebounce)
		{
			if(POWERON_1>2000) // Detecing Switch off for trigger action
			{
				if(PWSW)
				{
					PWSW = 0;
				}
				else
				{
					PWSW = 1;
				}
				//PWSW = 1;
				POWERON_1 = REFdebounce +1;
				//POWERON_1 = REFdebounce +1;
			}

			else if ((POWERON_1> 150) & (POWERON_1< 250)) // Detecing Switch On for trigger action
				{
					//sensors &= ~( HAL_GPIO_ReadPin(CH1_1_GPIO_Port, CH1_1_Pin) << 23);
				if(SCANROOM)
					{
						SCANROOM = 0;
					}
				else
					{
						SCANROOM = 1;
					}
				}
			//POWERON_1 = REFdebounce +1;
			//POWERON_1 = REFdebounce +1;

			POWERON_State = 1;
		}
	}
		else
		{
			POWERON_1 =0;
			POWERON_0++;
			if(POWERON_0 >= REFdebounce)
			{
			POWERON_0 = REFdebounce +1 ;
			POWERON_State = 0;
			}
		}

if(SMOKEON != 1)  //Pressed
	{

		SMOKEON_1 ++; // Is a count var of button preess increment 1 by 1ms
		SMOKEON_0 = 0; // debounce the zero value
		if(SMOKEON_1 >= REFdebounce)
		{
			if(SMOKEON_1>150) // Detecing Switch off for trigger action
			{
				if(clear_1)
				{
				sensors =  sensors ^ (1 << 4);
				clear_1 = 0;
				}
				SMOKEON_1 = REFdebounce +1;
			}

		}
	}
		else
		{
			clear_1 = 1;
			SMOKEON_1 =0;
			SMOKEON_0++;
			if(SMOKEON_0 >= REFdebounce)
			{
			SMOKEON_0 = REFdebounce +1 ;
			}
		}

if(GASON != 1)  //Pressed
	{

		GASON_1 ++; // Is a count var of button preess increment 1 by 1ms
		GASON_0 = 0; // debounce the zero value
		if(GASON_1 >= REFdebounce)
		{
			if(GASON_1>150) // Detecing Switch off for trigger action
			{
				if(clear_2)
				{
				sensors =  sensors ^ (1 << 5);
				clear_2 = 0;
				}
				GASON_1 = REFdebounce +1;
			}

		}
	}
		else
		{
			clear_2 = 1;
			GASON_1 =0;
			GASON_0++;
			if(GASON_0 >= REFdebounce)
			{
			GASON_0 = REFdebounce +1 ;
			}
		}

if(MOVEON != 1)  //Pressed
	{

		MOVEON_1 ++; // Is a count var of button preess increment 1 by 1ms
		MOVEON_0 = 0; // debounce the zero value
		if(MOVEON_1 >= REFdebounce)
		{
			if(MOVEON_1>150) // Detecing Switch off for trigger action
			{
				if(clear_3)
				{
				sensors =  sensors ^ (1 << 7);
				motionFlag = 0x0;
				clear_3 = 0;
				}
				MOVEON_1 = REFdebounce +1;
			}
			motionFlag = 0x0;
		}
	}
		else
		{
			clear_3 = 1;
			MOVEON_1 =0;
			MOVEON_0++;
			if(MOVEON_0 >= REFdebounce)
			{
			MOVEON_0 = REFdebounce +1 ;
			}
		}

if(NITEON != 1)  //Pressed
	{

		NITEON_1 ++; // Is a count var of button preess increment 1 by 1ms
		NITEON_0 = 0; // debounce the zero value
		if(NITEON_1 >= REFdebounce)
		{
			if(NITEON_1>150) // Detecing Switch off for trigger action
			{
				if(clear_4)
				{
				sensors =  sensors ^ (1 << 6);
				clear_4 = 0;
				}
				NITEON_1 = REFdebounce +1;
			}

		}
	}
		else
		{
			clear_4 = 1;
			NITEON_1 =0;
			NITEON_0++;
			if(NITEON_0 >= REFdebounce)
			{
			NITEON_0 = REFdebounce +1 ;
			}
		}

if(SOUNDON != 1)  //Pressed
	{

		SOUNDON_1 ++; // Is a count var of button preess increment 1 by 1ms
		SOUNDON_0 = 0; // debounce the zero value
		if(SOUNDON_1 >= REFdebounce)
		{
			if(SOUNDON_1>150) // Detecing Switch off for trigger action
			{
				if(clear_5)
				{
				sensors =  sensors ^ (1 << 8);
				clear_5 = 0;
				}
				SOUNDON_1 = REFdebounce +1;
			}

		}
	}
		else
		{
			clear_5 = 1;
			SOUNDON_1 =0;
			SOUNDON_0++;
			if(SOUNDON_0 >= REFdebounce)
			{
			SOUNDON_0 = REFdebounce +1 ;
			}
		}

if(BTON != 1)  //Pressed
	{

		BTON_1 ++; // Is a count var of button preess increment 1 by 1ms
		BTON_0 = 0; // debounce the zero value
		if(BTON_1 >= REFdebounce)
		{
			if(BTON_1>150) // Detecing Switch off for trigger action
			{
				if(clear_6)
				{
				sensors =  sensors ^ (1 << 9);
				clear_6 = 0;
				}
				BTON_1 = REFdebounce +1;
			}

		}
	}
		else
		{
			clear_6 = 1;
			BTON_1 =0;
			BTON_0++;
			if(BTON_0 >= REFdebounce)
			{
			BTON_0 = REFdebounce +1 ;
			}
		}

	if(countHeater)
	{
		heaterTime ++;
	}
	else
	{
		heaterTime = 0;
	}
	if(offCountHeater)
	{
		offHeaterTime ++;
	}
	else
	{
		offHeaterTime = 0;
	}

	//if the got trigger the light need to flash
	if(flashRED)
	{
		flashredTime ++;
	}

}

void startupF(void)
{

	for(int x = 0; x<40; )
  {

		HAL_GPIO_WritePin(RING_R_GPIO_Port, RING_R_Pin, GPIO_PIN_SET);
		HAL_GPIO_WritePin(RING_G_GPIO_Port, RING_G_Pin, GPIO_PIN_SET);
		HAL_GPIO_WritePin(RING_B_GPIO_Port, RING_B_Pin, GPIO_PIN_SET);
		TIM16->CCR1= x;
		x=x+5;
		HAL_Delay(250);
		switch (x)
      {
      	case 15:
					HAL_GPIO_WritePin(G4_GPIO_Port,G4_Pin,GPIO_PIN_SET);
      		break;
      	case 25:
					HAL_GPIO_WritePin(G6_GPIO_Port,G6_Pin,GPIO_PIN_SET); //NT
					HAL_GPIO_WritePin(G5_GPIO_Port,G5_Pin,GPIO_PIN_SET); //BLE
					HAL_GPIO_WritePin(G3_GPIO_Port,G3_Pin,GPIO_PIN_SET); //GS
					HAL_GPIO_WritePin(G2_GPIO_Port,G2_Pin,GPIO_PIN_SET); // Smoke
      		break;
				case 40:
					HAL_GPIO_WritePin(G1_GPIO_Port,G1_Pin,GPIO_PIN_SET);
      		break;
      	default:
      		break;
      }

  }

	for(uint8_t i =0; i<4; i++)
	{
		HAL_GPIO_TogglePin(RING_R_GPIO_Port, RING_R_Pin);
		HAL_GPIO_TogglePin(RING_G_GPIO_Port, RING_G_Pin);
		HAL_GPIO_TogglePin(RING_B_GPIO_Port, RING_B_Pin);

		HAL_Delay(1000);
	}

		HAL_GPIO_WritePin(RING_R_GPIO_Port, RING_R_Pin, GPIO_PIN_SET);
		HAL_GPIO_WritePin(RING_G_GPIO_Port, RING_G_Pin, GPIO_PIN_SET);
		HAL_GPIO_WritePin(RING_B_GPIO_Port, RING_B_Pin, GPIO_PIN_SET);

}

void shutF(void)
{

	for(int x = 40; x>0; )
  {

		HAL_GPIO_WritePin(RING_R_GPIO_Port, RING_R_Pin, GPIO_PIN_SET);
		HAL_GPIO_WritePin(RING_G_GPIO_Port, RING_G_Pin, GPIO_PIN_SET);
		HAL_GPIO_WritePin(RING_B_GPIO_Port, RING_B_Pin, GPIO_PIN_SET);
		TIM16->CCR1= x;
		x=x-5;
		HAL_Delay(250);
		switch (x)
      {
      	case 35:
					HAL_GPIO_WritePin(G4_GPIO_Port,G4_Pin,GPIO_PIN_RESET); //snd
      		break;
      	case 20:
					HAL_GPIO_WritePin(G6_GPIO_Port,G6_Pin,GPIO_PIN_RESET); //NT
					HAL_GPIO_WritePin(G5_GPIO_Port,G5_Pin,GPIO_PIN_RESET); //BLE
					HAL_GPIO_WritePin(G3_GPIO_Port,G3_Pin,GPIO_PIN_RESET); //GS
					HAL_GPIO_WritePin(G2_GPIO_Port,G2_Pin,GPIO_PIN_RESET); // Smoke
      		break;
				case 15:
					HAL_GPIO_WritePin(G1_GPIO_Port,G1_Pin,GPIO_PIN_RESET); // motion
      		break;
      	default:
      		break;
      }

  }

	for(uint8_t i =0; i<4; i++)
	{
		HAL_GPIO_TogglePin(RING_R_GPIO_Port, RING_R_Pin);
		HAL_GPIO_TogglePin(RING_G_GPIO_Port, RING_G_Pin);
		HAL_GPIO_TogglePin(RING_B_GPIO_Port, RING_B_Pin);

		HAL_Delay(1000);
	}

		HAL_GPIO_WritePin(RING_R_GPIO_Port, RING_R_Pin, GPIO_PIN_RESET);
		HAL_GPIO_WritePin(RING_G_GPIO_Port, RING_G_Pin, GPIO_PIN_RESET);
		HAL_GPIO_WritePin(RING_B_GPIO_Port, RING_B_Pin, GPIO_PIN_RESET);

}

void heartBeat_loop(uint8_t initial_val, uint8_t end_val, uint8_t n)
{
		int delayl = 0;
		HAL_GPIO_WritePin(RING_B_GPIO_Port, RING_B_Pin, GPIO_PIN_SET);
	//only run this loop when the initial value max = 40
		if(n==0) // when light ramp down slope
	{
			for(uint8_t x = initial_val; x>=end_val;) // 0- 100 in 2 sec
			{
			TIM16->CCR1= x;
			x = x - 1;

			//Detect 13 times 10ms of TIM6 has elapsed.
			delayl = 1000/(initial_val-end_val);
			HAL_Delay(delayl);

			//Create a delay of 130ms
			//loop will end with PWM val = 10 so 25% brightness
			}
	}
	//carry this loop when initial value is at lowest = 20
		else if (n == 1)// up slope
	{
			for(uint8_t x = initial_val; x<=end_val;)
			{
			TIM16->CCR1= x;
			x = x + 1;
			delayl = 1000/(end_val-initial_val);
			//Create a delay of 130ms

			HAL_Delay(delayl);
			//loop will end with PWM val = 10 so 25% brightness
			}
	}
}

void heartBeat_loop2(uint8_t initial_val, uint8_t end_val, uint8_t n)
{
		int delayl = 0;
		HAL_GPIO_WritePin(RING_B_GPIO_Port, RING_B_Pin, GPIO_PIN_SET);
	//only run this loop when the initial value max = 40
		if(n==0) // when light ramp down slope
	{
			for(uint8_t x = initial_val; x>=end_val;) // 0- 100 in 2 sec
			{
			TIM16->CCR1= x;
			x = x - 1;

			//Detect 13 times 10ms of TIM6 has elapsed.
			delayl = 2000/(initial_val-end_val);
			HAL_Delay(delayl);

			//Create a delay of 130ms
			//loop will end with PWM val = 10 so 25% brightness
			}
	}
	//carry this loop when initial value is at lowest = 20
		else if (n == 1)// up slope
	{
			for(uint8_t x = initial_val; x<=end_val;)
			{
			TIM16->CCR1= x;
			x = x + 1;
			delayl = 2000/(end_val-initial_val);
			//Create a delay of 130ms

			HAL_Delay(delayl);
			//loop will end with PWM val = 10 so 25% brightness
			}
	}
}

void HAL_SAI_TxCpltCallback(SAI_HandleTypeDef *hsai)
{
  /* NOTE : This function Should not be modified, when the callback is needed,
            the HAL_SAI_TxCpltCallback could be implemented in the user file
   */
  UpdatePointer = PLAY_BUFF_SIZE/2;
}

void HAL_SAI_TxHalfCpltCallback(SAI_HandleTypeDef *hsai)
{
  /* NOTE : This function Should not be modified, when the callback is needed,
            the HAL_SAI_TxHalfCpltCallback could be implenetd in the user file
   */
  UpdatePointer = 0;
}

void readSensors()
{
if(countHeater)
	{
	HAL_GPIO_WritePin(C0_HTR_GPIO_Port,C0_HTR_Pin, GPIO_PIN_SET);
	HAL_GPIO_WritePin(GAS_HTR_GPIO_Port,GAS_HTR_Pin, GPIO_PIN_SET);
	HAL_GPIO_WritePin(SMOKE_HTR_GPIO_Port,SMOKE_HTR_Pin, GPIO_PIN_SET);
	}
if(heaterTime >= 3000U)
	{
		//readValues analog/Digital.
		HAL_ADC_Stop(&hadc1);
		HAL_Delay(5);
		HAL_ADC_Start(&hadc1);

		HAL_ADC_PollForConversion(&hadc1,100);
		flame_a0 =  HAL_ADC_GetValue(&hadc1);
		flameV = ((2.05*flame_a0)/4096.0);

		HAL_ADC_PollForConversion(&hadc1,100);
		CO_a1 =  HAL_ADC_GetValue(&hadc1);
		coV = ((2.05*CO_a1)/4096.0);

		HAL_ADC_PollForConversion(&hadc1,100);
		smoke_a2 =  HAL_ADC_GetValue(&hadc1);

		smokeV = ((2.05*smoke_a2)/4096.0);

		HAL_ADC_Stop(&hadc1);

		countHeater = 0x00;
		HAL_GPIO_WritePin(C0_HTR_GPIO_Port,C0_HTR_Pin, GPIO_PIN_RESET);
		HAL_GPIO_WritePin(GAS_HTR_GPIO_Port,GAS_HTR_Pin, GPIO_PIN_RESET);
		HAL_GPIO_WritePin(SMOKE_HTR_GPIO_Port,SMOKE_HTR_Pin, GPIO_PIN_RESET);

		//Turn on counter for 30 Seconds.
		offCountHeater = 0x01;
	}
if(offHeaterTime >=3000U)
	{
		offCountHeater = 0x0;
		countHeater = 0x01;
	}

	temp_hum();

}

void checkDiff()
{
	//Read initial data into a variable
	if(sensors != sensorsM)
	{
		//Save the latest value to memory
	}
}

void trigger()
{
	//battery voltage
	//co sensor  done
	//flame sensor done
	//smoke sensors done

	if((flameV >= 0.8) || (coV >= 0.8) )
		{
			if(((sensors >> 5) & 1 ))
			{
			redCO = 1;
			}
			else
			{
			 redCO = 0;
			}

		}
		else
		{
			redCO = 0;
		}

		if(smokeV >=0.8)
		{
			if(((sensors >> 4) & 1 ))
			{
			redSmoke =1;
			}
			else
			{
			redSmoke =0;
			}
		}
		else
		{
			redSmoke = 0;
		}

		if(redCO || redSmoke || (motionFlag & ((sensors >> 7) & 1)))
		{
			flashRED = 0x01;
			if(0 != audio_drv->Play(AUDIO_I2C_ADDRESS, NULL, 0))
				{
					Error_Handler();
				}
		}
		else
		{
			flashRED = 0x00;
			firsttimeonly = 0x01;
			HAL_SAI_DMAPause(&hsai_BlockA1); // dma pause don't send music also the buffer
			//might need to eplicit pause the audio chip

		}

		if((flashredTime > 1000U) & (flashRED) )
		{
			HAL_GPIO_WritePin(RING_B_GPIO_Port, RING_B_Pin, GPIO_PIN_RESET);
			HAL_GPIO_WritePin(RING_G_GPIO_Port, RING_G_Pin, GPIO_PIN_RESET);
			HAL_GPIO_TogglePin(RING_R_GPIO_Port,RING_R_Pin);
			flashredTime = 0;
		}

		if(!flashRED)
		{
			HAL_GPIO_WritePin(RING_B_GPIO_Port, RING_B_Pin, GPIO_PIN_SET);
			HAL_GPIO_WritePin(RING_G_GPIO_Port, RING_G_Pin, GPIO_PIN_RESET);
			HAL_GPIO_WritePin(RING_R_GPIO_Port, RING_R_Pin, GPIO_PIN_RESET);
		}

}

void HAL_GPIO_EXTI_Callback(uint16_t GPIO_Pin)
{
	if(GPIO_Pin == INT_2_Pin)
	{
		motionFlag = 0x01U;
	}
}

void temp_hum()
{
		reg1 = 0xE5; // hold master signal
	HAL_I2C_Mem_Read(&hi2c1, TEMP_ADD, reg1,I2C_MEMADD_SIZE_8BIT, temph, 2, 1000);
	R_HUM = (uint16_t) ((temph[0]<<8) | temph[1]);
	A_HUM = (float)(((125.0 * R_HUM) / 65536.0) - 6.0);
	if(A_HUM < 0)
    A_HUM =  0;
  else if(A_HUM > 100)
    A_HUM = 100;

	reg1 = 0xE0;

	HAL_I2C_Mem_Read(&hi2c1, TEMP_ADD, reg1,I2C_MEMADD_SIZE_8BIT, temph, 2, 1000);
	R_TEMP = (uint16_t) ((temph[0]<<8) | temph[1]);
	A_TEMP = (float)(((175.72 * R_TEMP) / 65536.0) - 46.85);
}
/* USER CODE END 4 */

void _Error_Handler(char *file, int line)
{
  while(1)
  {
  }
}

/************************ (C) COPYRIGHT STMicroelectronics *****END OF FILE****/
